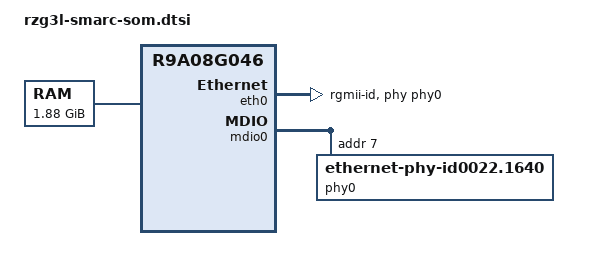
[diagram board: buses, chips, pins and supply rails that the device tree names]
// SPDX-License-Identifier: (GPL-2.0-only OR BSD-2-Clause)
/*
 * Device Tree Source for R9A08G046L48 SMARC SoM board.
 *
 * Copyright (C) 2026 Renesas Electronics Corp.
 */

/ {
	compatible = "renesas,rzg3l-smarcm", "renesas,r9a08g046l48", "renesas,r9a08g046";

	aliases {
		ethernet0 = &eth0;
	};

	memory@48000000 {
		device_type = "memory";
		/* First 128MiB is reserved for secure area. */
		reg = <0x0 0x48000000 0x0 0x78000000>;
	};
};

&eth0 {
	phy-handle = <&phy0>;
	phy-mode = "rgmii-id";

	status = "okay";
};

&eth0_rxc_rx_clk {
	clock-frequency = <125000000>;
};

&extal_clk {
	clock-frequency = <24000000>;
};

&mdio0 {
	phy0: ethernet-phy@7 {
		compatible = "ethernet-phy-id0022.1640";
		reg = <7>;
		rxc-skew-psec = <1400>;
		txc-skew-psec = <1400>;
		rxdv-skew-psec = <0>;
		txen-skew-psec = <0>;
		rxd0-skew-psec = <0>;
		rxd1-skew-psec = <0>;
		rxd2-skew-psec = <0>;
		rxd3-skew-psec = <0>;
		txd0-skew-psec = <0>;
		txd1-skew-psec = <0>;
		txd2-skew-psec = <0>;
		txd3-skew-psec = <0>;
	};
};
